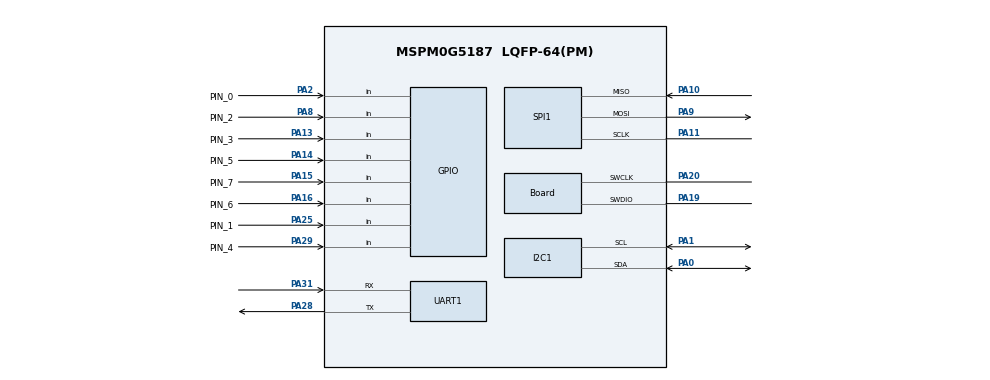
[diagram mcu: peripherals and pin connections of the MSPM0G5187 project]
//@cliArgs --device "MSPM0G518X" --package "LQFP-64(PM)" --part "Default"
//@v2CliArgs --device "MSPM0G5187" --package "LQFP-64(PM)"
// @cliArgs --board /ti/boards/LP_MSPM0G5187 --rtos nortos

/**
 * Import the modules used in this configuration.
 */
const Board         = scripting.addModule("/ti/driverlib/Board");
const GPIO          = scripting.addModule("/ti/driverlib/GPIO", {}, false);
const GPIO1         = GPIO.addInstance();
const I2C           = scripting.addModule("/ti/driverlib/I2C", {}, false);
const I2C1          = I2C.addInstance();
const SPI           = scripting.addModule("/ti/driverlib/SPI", {}, false);
const SPI1          = SPI.addInstance();
const SYSCTL        = scripting.addModule("/ti/driverlib/SYSCTL");
const UART          = scripting.addModule("/ti/driverlib/UART", {}, false);
const UART1         = UART.addInstance();
const ProjectConfig = scripting.addModule("/ti/project_config/ProjectConfig");

/**
 * Write custom configuration values to the imported modules.
 */
Board.peripheral.$assign          = "DEBUGSS";
Board.peripheral.swclkPin.$assign = "PA20";
Board.peripheral.swdioPin.$assign = "PA19";

GPIO1.$name                          = "GPIO_GRP_0";
GPIO1.associatedPins.create(8);
GPIO1.associatedPins[0].$name        = "PIN_0";
GPIO1.associatedPins[0].assignedPin  = "2";
GPIO1.associatedPins[0].assignedPort = "PORTA";
GPIO1.associatedPins[0].direction    = "INPUT";
GPIO1.associatedPins[0].pin.$assign  = "PA2";
GPIO1.associatedPins[1].$name        = "PIN_1";
GPIO1.associatedPins[1].direction    = "INPUT";
GPIO1.associatedPins[1].assignedPort = "PORTA";
GPIO1.associatedPins[1].assignedPin  = "25";
GPIO1.associatedPins[1].pin.$assign  = "PA25";
GPIO1.associatedPins[2].$name        = "PIN_2";
GPIO1.associatedPins[2].assignedPort = "PORTA";
GPIO1.associatedPins[2].direction    = "INPUT";
GPIO1.associatedPins[2].assignedPin  = "8";
GPIO1.associatedPins[2].pin.$assign  = "PA8";
GPIO1.associatedPins[3].$name        = "PIN_3";
GPIO1.associatedPins[3].assignedPort = "PORTA";
GPIO1.associatedPins[3].direction    = "INPUT";
GPIO1.associatedPins[3].assignedPin  = "13";
GPIO1.associatedPins[3].pin.$assign  = "PA13";
GPIO1.associatedPins[4].$name        = "PIN_4";
GPIO1.associatedPins[4].assignedPort = "PORTA";
GPIO1.associatedPins[4].direction    = "INPUT";
GPIO1.associatedPins[4].assignedPin  = "29";
GPIO1.associatedPins[4].pin.$assign  = "PA29";
GPIO1.associatedPins[5].$name        = "PIN_5";
GPIO1.associatedPins[5].assignedPort = "PORTA";
GPIO1.associatedPins[5].direction    = "INPUT";
GPIO1.associatedPins[5].assignedPin  = "14";
GPIO1.associatedPins[5].pin.$assign  = "PA14";
GPIO1.associatedPins[6].$name        = "PIN_6";
GPIO1.associatedPins[6].assignedPort = "PORTA";
GPIO1.associatedPins[6].assignedPin  = "16";
GPIO1.associatedPins[6].direction    = "INPUT";
GPIO1.associatedPins[6].pin.$assign  = "PA16";
GPIO1.associatedPins[7].$name        = "PIN_7";
GPIO1.associatedPins[7].direction    = "INPUT";
GPIO1.associatedPins[7].assignedPort = "PORTA";
GPIO1.associatedPins[7].assignedPin  = "15";
GPIO1.associatedPins[7].pin.$assign  = "PA15";

I2C1.$name                             = "I2C";
I2C1.basicControllerBusSpeed           = 400000;
I2C1.basicTargetAddress                = 0x48;
I2C1.basicEnableTarget                 = true;
I2C1.advTargetTXEmptyEn                = true;
I2C1.intTarget                         = ["RXFIFO_TRIGGER","START","TXFIFO_EMPTY"];
I2C1.enableAnalogGlitchFilter          = true;
I2C1.peripheral.$assign                = "UC0";
I2C1.peripheral.sdaPin.$assign         = "PA0";
I2C1.peripheral.sclPin.$assign         = "PA1";

SPI1.$name                              = "SPI_0";
SPI1.frameFormat                        = "MOTO3";
SPI1.enabledInterrupts                  = ["RX"];
SPI1.mode                               = "PERIPHERAL";
SPI1.rxFifoThreshold                    = "DL_SPI_RX_FIFO_LEVEL_ONE_FRAME";
SPI1.txFifoThreshold                    = "DL_SPI_TX_FIFO_LEVEL_3_4_EMPTY";
SPI1.peripheral.$assign                 = "UC2";
SPI1.peripheral.sclkPin.$assign         = "PA11";
SPI1.peripheral.mosiPin.$assign         = "PA9";
SPI1.peripheral.misoPin.$assign         = "PA10";

SYSCTL.clockTreeEn    = true;
SYSCTL.disableNRSTPin = true;

UART1.$name                    = "UART_0";
UART1.enabledInterrupts        = ["RX"];
UART1.peripheral.$assign       = "UC1";
UART1.peripheral.rxPin.$assign = "PA31";
UART1.peripheral.txPin.$assign = "PA28";

ProjectConfig.migrationCondition = true;
